# CY8C5888LTI_LP097 register map
File version: 0.1
CY8C58LP
Registers are 8-bit, read-write, no defined reset value unless marked. A register's access mark holds for its fields unless they carry their own. Offsets are from the block's base; lines under a group give offsets from that group; [hi:lo] are bit positions; {n}, {i} and the like mark numbered series; 'fields as' and 'values as' point back to an identical list; <NAME> marks a mode.

## Memory map
0x00000000 RST
0x00000000 ROD
0x00000000 RRD
0x00000000 RCU
0x00000000 BusDta
0x00000000 ADL_Reg
0x00000000 DT_Reg
0x00000000 ADH_Reg
0x00000000 UART
0x00000000 USBUART — USBFS
0x00000000 I2COLED
0x00000000 RCM
0x00000000 SRAM_Ctl
0x00000000 RSU
0x00000000 RSM
0x00000000 Millis

## RST
Base 0x00000000
0x40006464 RST_STATUS_REG
0x40006484 RST_MASK_REG
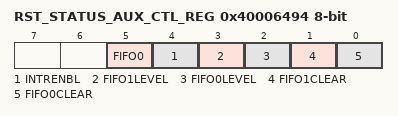
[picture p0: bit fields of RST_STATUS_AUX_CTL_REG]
0x40006494 RST_STATUS_AUX_CTL_REG
  [5] FIFO0 — FIFO0 clear
    1=ENABLED (Enable counter); 0=DISABLED (Disable counter)
  [4] INTRENBL — Enables or disables the Interrupt
    1=ENABLED (Interrupt enabled); 0=DISABLED (Interrupt disabled)
  [3] FIFO1LEVEL — FIFO level
    1=ENABLED (FIFO LVL: input mode: FIFO at least 1/2 empty; output mode: FIFO at least 1/2 full); 0=DISABLED (FIFO LVL: input mode: FIFO not full; output mode: FIFO not empty)
  [2] FIFO0LEVEL — FIFO level
    values as FIFO1LEVEL
  [1] FIFO1CLEAR — FIFO clear
    1=ENABLED (Clear FIFO state); 0=DISABLED (Normal FIFO operation)
  [0] FIFO0CLEAR — FIFO clear
    values as FIFO1CLEAR

## ROD
Base 0x00000000
0x4000646F ROD_STATUS_REG
0x4000648F ROD_MASK_REG
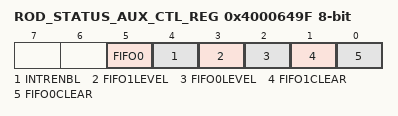
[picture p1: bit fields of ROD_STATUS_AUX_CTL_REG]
0x4000649F ROD_STATUS_AUX_CTL_REG
  [5] FIFO0 — FIFO0 clear
    1=ENABLED (Enable counter); 0=DISABLED (Disable counter)
  [4] INTRENBL — Enables or disables the Interrupt
    1=ENABLED (Interrupt enabled); 0=DISABLED (Interrupt disabled)
  [3] FIFO1LEVEL — FIFO level
    1=ENABLED (FIFO LVL: input mode: FIFO at least 1/2 empty; output mode: FIFO at least 1/2 full); 0=DISABLED (FIFO LVL: input mode: FIFO not full; output mode: FIFO not empty)
  [2] FIFO0LEVEL — FIFO level
    values as FIFO1LEVEL
  [1] FIFO1CLEAR — FIFO clear
    1=ENABLED (Clear FIFO state); 0=DISABLED (Normal FIFO operation)
  [0] FIFO0CLEAR — FIFO clear
    values as FIFO1CLEAR

## RRD
Base 0x00000000
0x40006472 RRD_CONTROL_REG

## RCU
Base 0x00000000
0x40006465 RCU_STATUS_REG
0x40006485 RCU_MASK_REG
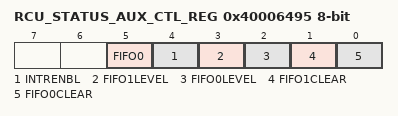
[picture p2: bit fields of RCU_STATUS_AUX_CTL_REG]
0x40006495 RCU_STATUS_AUX_CTL_REG
  [5] FIFO0 — FIFO0 clear
    1=ENABLED (Enable counter); 0=DISABLED (Disable counter)
  [4] INTRENBL — Enables or disables the Interrupt
    1=ENABLED (Interrupt enabled); 0=DISABLED (Interrupt disabled)
  [3] FIFO1LEVEL — FIFO level
    1=ENABLED (FIFO LVL: input mode: FIFO at least 1/2 empty; output mode: FIFO at least 1/2 full); 0=DISABLED (FIFO LVL: input mode: FIFO not full; output mode: FIFO not empty)
  [2] FIFO0LEVEL — FIFO level
    values as FIFO1LEVEL
  [1] FIFO1CLEAR — FIFO clear
    1=ENABLED (Clear FIFO state); 0=DISABLED (Normal FIFO operation)
  [0] FIFO0CLEAR — FIFO clear
    values as FIFO1CLEAR

## BusDta
Base 0x00000000
0x40006473 BusDta_CONTROL_REG

## ADL_Reg
Base 0x00000000
0x40006469 ADL_Reg_STATUS_REG
0x40006489 ADL_Reg_MASK_REG
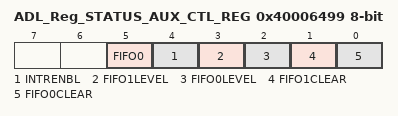
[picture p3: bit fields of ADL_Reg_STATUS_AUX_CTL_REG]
0x40006499 ADL_Reg_STATUS_AUX_CTL_REG
  [5] FIFO0 — FIFO0 clear
    1=ENABLED (Enable counter); 0=DISABLED (Disable counter)
  [4] INTRENBL — Enables or disables the Interrupt
    1=ENABLED (Interrupt enabled); 0=DISABLED (Interrupt disabled)
  [3] FIFO1LEVEL — FIFO level
    1=ENABLED (FIFO LVL: input mode: FIFO at least 1/2 empty; output mode: FIFO at least 1/2 full); 0=DISABLED (FIFO LVL: input mode: FIFO not full; output mode: FIFO not empty)
  [2] FIFO0LEVEL — FIFO level
    values as FIFO1LEVEL
  [1] FIFO1CLEAR — FIFO clear
    1=ENABLED (Clear FIFO state); 0=DISABLED (Normal FIFO operation)
  [0] FIFO0CLEAR — FIFO clear
    values as FIFO1CLEAR

## DT_Reg
Base 0x00000000
0x40006461 DT_Reg_STATUS_REG
0x40006481 DT_Reg_MASK_REG
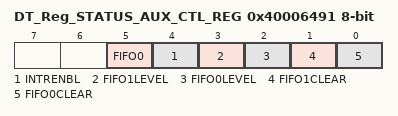
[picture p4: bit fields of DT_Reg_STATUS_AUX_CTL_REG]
0x40006491 DT_Reg_STATUS_AUX_CTL_REG
  [5] FIFO0 — FIFO0 clear
    1=ENABLED (Enable counter); 0=DISABLED (Disable counter)
  [4] INTRENBL — Enables or disables the Interrupt
    1=ENABLED (Interrupt enabled); 0=DISABLED (Interrupt disabled)
  [3] FIFO1LEVEL — FIFO level
    1=ENABLED (FIFO LVL: input mode: FIFO at least 1/2 empty; output mode: FIFO at least 1/2 full); 0=DISABLED (FIFO LVL: input mode: FIFO not full; output mode: FIFO not empty)
  [2] FIFO0LEVEL — FIFO level
    values as FIFO1LEVEL
  [1] FIFO1CLEAR — FIFO clear
    1=ENABLED (Clear FIFO state); 0=DISABLED (Normal FIFO operation)
  [0] FIFO0CLEAR — FIFO clear
    values as FIFO1CLEAR
